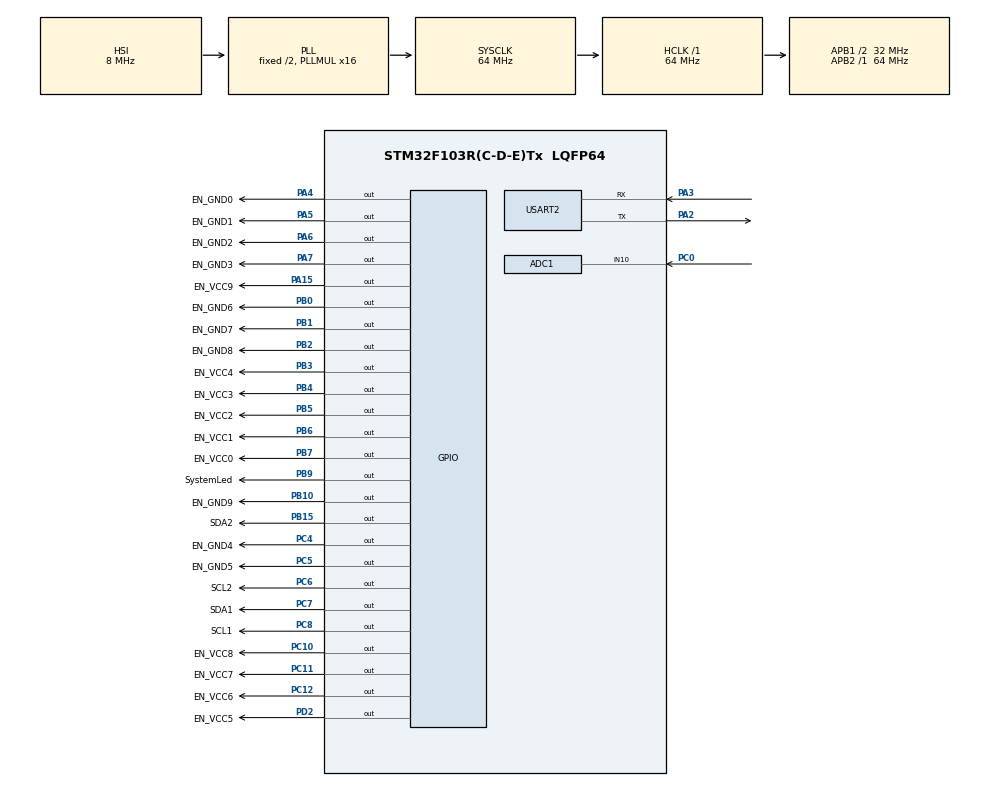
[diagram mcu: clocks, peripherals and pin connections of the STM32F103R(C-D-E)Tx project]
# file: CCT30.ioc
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ADC1.Channel-1\#ChannelRegularConversion=ADC_CHANNEL_10
ADC1.Channel-2\#ChannelRegularConversion=ADC_CHANNEL_TEMPSENSOR
ADC1.Channel-3\#ChannelRegularConversion=ADC_CHANNEL_VREFINT
ADC1.NbrOfConversion=3
ADC1.NbrOfConversionFlag=1
ADC1.Rank-1\#ChannelRegularConversion=1
ADC1.Rank-2\#ChannelRegularConversion=2
ADC1.Rank-3\#ChannelRegularConversion=3
ADC1.SamplingTime-1\#ChannelRegularConversion=ADC_SAMPLETIME_239CYCLES_5
ADC1.SamplingTime-2\#ChannelRegularConversion=ADC_SAMPLETIME_239CYCLES_5
ADC1.SamplingTime-3\#ChannelRegularConversion=ADC_SAMPLETIME_239CYCLES_5
ADC1.master=1
Dma.ADC1.0.Direction=DMA_PERIPH_TO_MEMORY
Dma.ADC1.0.Instance=DMA1_Channel1
Dma.ADC1.0.MemDataAlignment=DMA_MDATAALIGN_WORD
Dma.ADC1.0.MemInc=DMA_MINC_ENABLE
Dma.ADC1.0.Mode=DMA_CIRCULAR
Dma.ADC1.0.PeriphDataAlignment=DMA_PDATAALIGN_WORD
Dma.ADC1.0.PeriphInc=DMA_PINC_DISABLE
Dma.ADC1.0.Priority=DMA_PRIORITY_LOW
Dma.Request0=ADC1
Dma.Request1=USART2_RX
Dma.USART2_RX.1.Direction=DMA_PERIPH_TO_MEMORY
Dma.USART2_RX.1.Instance=DMA1_Channel6
Dma.USART2_RX.1.MemDataAlignment=DMA_MDATAALIGN_BYTE
Dma.USART2_RX.1.MemInc=DMA_MINC_ENABLE
Dma.USART2_RX.1.Mode=DMA_NORMAL
Dma.USART2_RX.1.PeriphDataAlignment=DMA_PDATAALIGN_BYTE
Dma.USART2_RX.1.PeriphInc=DMA_PINC_DISABLE
Dma.USART2_RX.1.Priority=DMA_PRIORITY_LOW
Mcu.Family=STM32F1
Mcu.Name=STM32F103R(C-D-E)Tx
Mcu.Package=LQFP64
NVIC.DMA1_Channel1_IRQn=true\:0\:0\:false\:false\:true\:false\:true\:true
NVIC.DMA1_Channel6_IRQn=true\:0\:0\:false\:false\:true\:false\:true\:true
NVIC.PriorityGroup=NVIC_PRIORITYGROUP_4
NVIC.USART2_IRQn=true\:0\:0\:false\:false\:true\:true\:true\:true
PA13.Mode=Serial_Wire
PA13.Signal=SYS_JTMS-SWDIO
PA14.Mode=Serial_Wire
PA14.Signal=SYS_JTCK-SWCLK
PA15.GPIO_Label=EN_VCC9
PA15.GPIO_ModeDefaultOutputPP=GPIO_MODE_OUTPUT_PP
PA15.GPIO_PuPd=GPIO_NOPULL
PA15.GPIO_Speed=GPIO_SPEED_FREQ_HIGH
PA15.PinState=GPIO_PIN_RESET
PA15.Signal=GPIO_Output
PA2.Mode=Asynchronous
PA2.Signal=USART2_TX
PA3.Mode=Asynchronous
PA3.Signal=USART2_RX
PA4.GPIO_Label=EN_GND0
PA4.GPIO_ModeDefaultOutputPP=GPIO_MODE_OUTPUT_PP
PA4.GPIO_PuPd=GPIO_NOPULL
PA4.GPIO_Speed=GPIO_SPEED_FREQ_HIGH
PA4.PinState=GPIO_PIN_RESET
PA4.Signal=GPIO_Output
PA5.GPIO_Label=EN_GND1
PA5.GPIO_ModeDefaultOutputPP=GPIO_MODE_OUTPUT_PP
PA5.GPIO_PuPd=GPIO_NOPULL
PA5.GPIO_Speed=GPIO_SPEED_FREQ_HIGH
PA5.PinState=GPIO_PIN_RESET
PA5.Signal=GPIO_Output
PA6.GPIO_Label=EN_GND2
PA6.GPIO_ModeDefaultOutputPP=GPIO_MODE_OUTPUT_PP
PA6.GPIO_PuPd=GPIO_NOPULL
PA6.GPIO_Speed=GPIO_SPEED_FREQ_HIGH
PA6.PinState=GPIO_PIN_RESET
PA6.Signal=GPIO_Output
PA7.GPIO_Label=EN_GND3
PA7.GPIO_ModeDefaultOutputPP=GPIO_MODE_OUTPUT_PP
PA7.GPIO_PuPd=GPIO_NOPULL
PA7.GPIO_Speed=GPIO_SPEED_FREQ_HIGH
PA7.PinState=GPIO_PIN_RESET
PA7.Signal=GPIO_Output
PB0.GPIO_Label=EN_GND6
PB0.GPIO_ModeDefaultOutputPP=GPIO_MODE_OUTPUT_PP
PB0.GPIO_PuPd=GPIO_NOPULL
PB0.GPIO_Speed=GPIO_SPEED_FREQ_HIGH
PB0.PinState=GPIO_PIN_RESET
PB0.Signal=GPIO_Output
PB1.GPIO_Label=EN_GND7
PB1.GPIO_ModeDefaultOutputPP=GPIO_MODE_OUTPUT_PP
PB1.GPIO_PuPd=GPIO_NOPULL
PB1.GPIO_Speed=GPIO_SPEED_FREQ_HIGH
PB1.PinState=GPIO_PIN_RESET
PB1.Signal=GPIO_Output
PB10.GPIO_Label=EN_GND9
PB10.GPIO_ModeDefaultOutputPP=GPIO_MODE_OUTPUT_PP
PB10.GPIO_PuPd=GPIO_NOPULL
PB10.GPIO_Speed=GPIO_SPEED_FREQ_HIGH
PB10.PinState=GPIO_PIN_RESET
PB10.Signal=GPIO_Output
PB15.GPIO_Label=SDA2
PB15.GPIO_ModeDefaultOutputPP=GPIO_MODE_OUTPUT_PP
PB15.GPIO_PuPd=GPIO_NOPULL
PB15.GPIO_Speed=GPIO_SPEED_FREQ_HIGH
PB15.PinState=GPIO_PIN_RESET
PB15.Signal=GPIO_Output
PB2.GPIO_Label=EN_GND8
PB2.GPIO_ModeDefaultOutputPP=GPIO_MODE_OUTPUT_PP
PB2.GPIO_PuPd=GPIO_NOPULL
PB2.GPIO_Speed=GPIO_SPEED_FREQ_HIGH
PB2.PinState=GPIO_PIN_RESET
PB2.Signal=GPIO_Output
PB3.GPIO_Label=EN_VCC4
PB3.GPIO_ModeDefaultOutputPP=GPIO_MODE_OUTPUT_PP
PB3.GPIO_PuPd=GPIO_NOPULL
PB3.GPIO_Speed=GPIO_SPEED_FREQ_HIGH
PB3.PinState=GPIO_PIN_RESET
PB3.Signal=GPIO_Output
PB4.GPIO_Label=EN_VCC3
PB4.GPIO_ModeDefaultOutputPP=GPIO_MODE_OUTPUT_PP
PB4.GPIO_PuPd=GPIO_NOPULL
PB4.GPIO_Speed=GPIO_SPEED_FREQ_HIGH
PB4.PinState=GPIO_PIN_RESET
PB4.Signal=GPIO_Output
PB5.GPIO_Label=EN_VCC2
PB5.GPIO_ModeDefaultOutputPP=GPIO_MODE_OUTPUT_PP
PB5.GPIO_PuPd=GPIO_NOPULL
PB5.GPIO_Speed=GPIO_SPEED_FREQ_HIGH
PB5.PinState=GPIO_PIN_RESET
PB5.Signal=GPIO_Output
PB6.GPIO_Label=EN_VCC1
PB6.GPIO_ModeDefaultOutputPP=GPIO_MODE_OUTPUT_PP
PB6.GPIO_PuPd=GPIO_NOPULL
PB6.GPIO_Speed=GPIO_SPEED_FREQ_HIGH
PB6.PinState=GPIO_PIN_RESET
PB6.Signal=GPIO_Output
PB7.GPIO_Label=EN_VCC0
PB7.GPIO_ModeDefaultOutputPP=GPIO_MODE_OUTPUT_PP
PB7.GPIO_PuPd=GPIO_NOPULL
PB7.GPIO_Speed=GPIO_SPEED_FREQ_HIGH
PB7.PinState=GPIO_PIN_RESET
PB7.Signal=GPIO_Output
PB9.GPIO_Label=SystemLed
PB9.Signal=GPIO_Output
PC0.Signal=ADCx_IN10
PC10.GPIO_Label=EN_VCC8
PC10.GPIO_ModeDefaultOutputPP=GPIO_MODE_OUTPUT_PP
PC10.GPIO_PuPd=GPIO_NOPULL
PC10.GPIO_Speed=GPIO_SPEED_FREQ_HIGH
PC10.PinState=GPIO_PIN_RESET
PC10.Signal=GPIO_Output
PC11.GPIO_Label=EN_VCC7
PC11.GPIO_ModeDefaultOutputPP=GPIO_MODE_OUTPUT_PP
PC11.GPIO_PuPd=GPIO_NOPULL
PC11.GPIO_Speed=GPIO_SPEED_FREQ_HIGH
PC11.PinState=GPIO_PIN_RESET
PC11.Signal=GPIO_Output
PC12.GPIO_Label=EN_VCC6
PC12.GPIO_ModeDefaultOutputPP=GPIO_MODE_OUTPUT_PP
PC12.GPIO_PuPd=GPIO_NOPULL
PC12.GPIO_Speed=GPIO_SPEED_FREQ_HIGH
PC12.PinState=GPIO_PIN_RESET
PC12.Signal=GPIO_Output
PC4.GPIO_Label=EN_GND4
PC4.GPIO_ModeDefaultOutputPP=GPIO_MODE_OUTPUT_PP
PC4.GPIO_PuPd=GPIO_NOPULL
PC4.GPIO_Speed=GPIO_SPEED_FREQ_HIGH
PC4.PinState=GPIO_PIN_RESET
PC4.Signal=GPIO_Output
PC5.GPIO_Label=EN_GND5
PC5.GPIO_ModeDefaultOutputPP=GPIO_MODE_OUTPUT_PP
PC5.GPIO_PuPd=GPIO_NOPULL
PC5.GPIO_Speed=GPIO_SPEED_FREQ_HIGH
PC5.PinState=GPIO_PIN_RESET
PC5.Signal=GPIO_Output
PC6.GPIO_Label=SCL2
PC6.GPIO_ModeDefaultOutputPP=GPIO_MODE_OUTPUT_PP
PC6.GPIO_PuPd=GPIO_NOPULL
PC6.GPIO_Speed=GPIO_SPEED_FREQ_HIGH
PC6.PinState=GPIO_PIN_RESET
PC6.Signal=GPIO_Output
PC7.GPIO_Label=SDA1
PC7.GPIO_ModeDefaultOutputPP=GPIO_MODE_OUTPUT_PP
PC7.GPIO_PuPd=GPIO_NOPULL
PC7.GPIO_Speed=GPIO_SPEED_FREQ_HIGH
PC7.PinState=GPIO_PIN_RESET
PC7.Signal=GPIO_Output
PC8.GPIO_Label=SCL1
PC8.GPIO_ModeDefaultOutputPP=GPIO_MODE_OUTPUT_PP
PC8.GPIO_PuPd=GPIO_NOPULL
PC8.GPIO_Speed=GPIO_SPEED_FREQ_HIGH
PC8.PinState=GPIO_PIN_RESET
PC8.Signal=GPIO_Output
PD2.GPIO_Label=EN_VCC5
PD2.GPIO_ModeDefaultOutputPP=GPIO_MODE_OUTPUT_PP
PD2.GPIO_PuPd=GPIO_NOPULL
PD2.GPIO_Speed=GPIO_SPEED_FREQ_HIGH
PD2.PinState=GPIO_PIN_RESET
PD2.Signal=GPIO_Output
ProjectManager.HeapSize=0x200
ProjectManager.StackSize=0x400
ProjectManager.TargetToolchain=MDK-ARM V5.32
RCC.ADCPresc=RCC_ADCPCLK2_DIV6
RCC.AHBFreq_Value=64000000
RCC.APB1CLKDivider=RCC_HCLK_DIV2
RCC.APB1Freq_Value=32000000
RCC.APB1TimFreq_Value=64000000
RCC.APB2Freq_Value=64000000
RCC.APB2TimFreq_Value=64000000
RCC.HCLKFreq_Value=64000000
RCC.PLLMUL=RCC_PLL_MUL16
RCC.SYSCLKFreq_VALUE=64000000
RCC.SYSCLKSource=RCC_SYSCLKSOURCE_PLLCLK
RCC.USBFreq_Value=64000000
SH.ADCx_IN10.0=ADC1_IN10,IN10
USART2.VirtualMode=VM_ASYNC
VP_ADC1_TempSens_Input.Mode=IN-TempSens
VP_ADC1_Vref_Input.Mode=IN-Vrefint
board=custom

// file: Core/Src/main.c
/* USER CODE BEGIN Header */
/**
  ******************************************************************************
  * @file           : main.c
  * @brief          : Main program body
  ******************************************************************************
  * @attention
  *
  * Copyright (c) 2023 STMicroelectronics.
  * All rights reserved.
  *
  * This software is licensed under terms that can be found in the LICENSE file
  * in the root directory of this software component.
  * If no LICENSE file comes with this software, it is provided AS-IS.
  *
  ******************************************************************************
  */
/* USER CODE END Header */
#include "main.h"

ADC_HandleTypeDef hadc1;
DMA_HandleTypeDef hdma_adc1;

UART_HandleTypeDef huart2;
DMA_HandleTypeDef hdma_usart2_rx;

void SystemClock_Config(void);
static void MX_GPIO_Init(void);
static void MX_DMA_Init(void);
static void MX_USART2_UART_Init(void);
static void MX_ADC1_Init(void);
/* USER CODE BEGIN PFP */
 void JQStart(void);
  void jSystemRun(void);
/* USER CODE END PFP */

int main(void)
{

  /* MCU Configuration--------------------------------------------------------*/

  /* Reset of all peripherals, Initializes the Flash interface and the Systick. */
  HAL_Init();

  /* Configure the system clock */
  SystemClock_Config();

  /* Initialize all configured peripherals */
  MX_GPIO_Init();
  MX_DMA_Init();
  MX_USART2_UART_Init();
  MX_ADC1_Init();

  /* Infinite loop */
  /* USER CODE BEGIN WHILE */
  while (1)
  {
		jSystemRun();
    /* USER CODE END WHILE */

  }
}

void SystemClock_Config(void)
{
  RCC_OscInitTypeDef RCC_OscInitStruct = {0};
  RCC_ClkInitTypeDef RCC_ClkInitStruct = {0};
  RCC_PeriphCLKInitTypeDef PeriphClkInit = {0};

  /** Initializes the RCC Oscillators according to the specified parameters
  * in the RCC_OscInitTypeDef structure.
  */
  RCC_OscInitStruct.OscillatorType = RCC_OSCILLATORTYPE_HSI;
  RCC_OscInitStruct.HSIState = RCC_HSI_ON;
  RCC_OscInitStruct.HSICalibrationValue = RCC_HSICALIBRATION_DEFAULT;
  RCC_OscInitStruct.PLL.PLLState = RCC_PLL_ON;
  RCC_OscInitStruct.PLL.PLLSource = RCC_PLLSOURCE_HSI_DIV2;
  RCC_OscInitStruct.PLL.PLLMUL = RCC_PLL_MUL16;
  if (HAL_RCC_OscConfig(&RCC_OscInitStruct) != HAL_OK)
  {
    Error_Handler();
  }

  /** Initializes the CPU, AHB and APB buses clocks
  */
  RCC_ClkInitStruct.ClockType = RCC_CLOCKTYPE_HCLK|RCC_CLOCKTYPE_SYSCLK
                              |RCC_CLOCKTYPE_PCLK1|RCC_CLOCKTYPE_PCLK2;
  RCC_ClkInitStruct.SYSCLKSource = RCC_SYSCLKSOURCE_PLLCLK;
  RCC_ClkInitStruct.AHBCLKDivider = RCC_SYSCLK_DIV1;
  RCC_ClkInitStruct.APB1CLKDivider = RCC_HCLK_DIV2;
  RCC_ClkInitStruct.APB2CLKDivider = RCC_HCLK_DIV1;

  if (HAL_RCC_ClockConfig(&RCC_ClkInitStruct, FLASH_LATENCY_2) != HAL_OK)
  {
    Error_Handler();
  }
  PeriphClkInit.PeriphClockSelection = RCC_PERIPHCLK_ADC;
  PeriphClkInit.AdcClockSelection = RCC_ADCPCLK2_DIV6;
  if (HAL_RCCEx_PeriphCLKConfig(&PeriphClkInit) != HAL_OK)
  {
    Error_Handler();
  }
}

static void MX_ADC1_Init(void)
{

  ADC_ChannelConfTypeDef sConfig = {0};

  /** Common config
  */
  hadc1.Instance = ADC1;
  hadc1.Init.ScanConvMode = ADC_SCAN_ENABLE;
  hadc1.Init.ContinuousConvMode = DISABLE;
  hadc1.Init.DiscontinuousConvMode = DISABLE;
  hadc1.Init.ExternalTrigConv = ADC_SOFTWARE_START;
  hadc1.Init.DataAlign = ADC_DATAALIGN_RIGHT;
  hadc1.Init.NbrOfConversion = 3;
  if (HAL_ADC_Init(&hadc1) != HAL_OK)
  {
    Error_Handler();
  }

  /** Configure Regular Channel
  */
  sConfig.Channel = ADC_CHANNEL_10;
  sConfig.Rank = ADC_REGULAR_RANK_1;
  sConfig.SamplingTime = ADC_SAMPLETIME_239CYCLES_5;
  if (HAL_ADC_ConfigChannel(&hadc1, &sConfig) != HAL_OK)
  {
    Error_Handler();
  }

  /** Configure Regular Channel
  */
  sConfig.Channel = ADC_CHANNEL_TEMPSENSOR;
  sConfig.Rank = ADC_REGULAR_RANK_2;
  if (HAL_ADC_ConfigChannel(&hadc1, &sConfig) != HAL_OK)
  {
    Error_Handler();
  }

  /** Configure Regular Channel
  */
  sConfig.Channel = ADC_CHANNEL_VREFINT;
  sConfig.Rank = ADC_REGULAR_RANK_3;
  if (HAL_ADC_ConfigChannel(&hadc1, &sConfig) != HAL_OK)
  {
    Error_Handler();
  }

}

static void MX_USART2_UART_Init(void)
{

  huart2.Instance = USART2;
  huart2.Init.BaudRate = 115200;
  huart2.Init.WordLength = UART_WORDLENGTH_8B;
  huart2.Init.StopBits = UART_STOPBITS_1;
  huart2.Init.Parity = UART_PARITY_NONE;
  huart2.Init.Mode = UART_MODE_TX_RX;
  huart2.Init.HwFlowCtl = UART_HWCONTROL_NONE;
  huart2.Init.OverSampling = UART_OVERSAMPLING_16;
  if (HAL_UART_Init(&huart2) != HAL_OK)
  {
    Error_Handler();
  }

}

static void MX_DMA_Init(void)
{

  /* DMA controller clock enable */
  __HAL_RCC_DMA1_CLK_ENABLE();

  /* DMA interrupt init */
  /* DMA1_Channel1_IRQn interrupt configuration */
  HAL_NVIC_SetPriority(DMA1_Channel1_IRQn, 0, 0);
  HAL_NVIC_EnableIRQ(DMA1_Channel1_IRQn);
  /* DMA1_Channel6_IRQn interrupt configuration */
  HAL_NVIC_SetPriority(DMA1_Channel6_IRQn, 0, 0);
  HAL_NVIC_EnableIRQ(DMA1_Channel6_IRQn);

}

static void MX_GPIO_Init(void)
{
  GPIO_InitTypeDef GPIO_InitStruct = {0};

  /* GPIO Ports Clock Enable */
  __HAL_RCC_GPIOC_CLK_ENABLE();
  __HAL_RCC_GPIOA_CLK_ENABLE();
  __HAL_RCC_GPIOB_CLK_ENABLE();
  __HAL_RCC_GPIOD_CLK_ENABLE();

  /*Configure GPIO pin Output Level */
  HAL_GPIO_WritePin(GPIOA, EN_GND0_Pin|EN_GND1_Pin|EN_GND2_Pin|EN_GND3_Pin
                          |EN_VCC9_Pin, GPIO_PIN_RESET);

  /*Configure GPIO pin Output Level */
  HAL_GPIO_WritePin(GPIOC, EN_GND4_Pin|EN_GND5_Pin|SCL2_Pin|SDA1_Pin
                          |SCL1_Pin|EN_VCC8_Pin|EN_VCC7_Pin|EN_VCC6_Pin, GPIO_PIN_RESET);

  /*Configure GPIO pin Output Level */
  HAL_GPIO_WritePin(GPIOB, EN_GND6_Pin|EN_GND7_Pin|EN_GND8_Pin|EN_GND9_Pin
                          |SDA2_Pin|EN_VCC4_Pin|EN_VCC3_Pin|EN_VCC2_Pin
                          |EN_VCC1_Pin|EN_VCC0_Pin|SystemLed_Pin, GPIO_PIN_RESET);

  /*Configure GPIO pin Output Level */
  HAL_GPIO_WritePin(EN_VCC5_GPIO_Port, EN_VCC5_Pin, GPIO_PIN_RESET);

  /*Configure GPIO pins : EN_GND0_Pin EN_GND1_Pin EN_GND2_Pin EN_GND3_Pin
                           EN_VCC9_Pin */
  GPIO_InitStruct.Pin = EN_GND0_Pin|EN_GND1_Pin|EN_GND2_Pin|EN_GND3_Pin
                          |EN_VCC9_Pin;
  GPIO_InitStruct.Mode = GPIO_MODE_OUTPUT_PP;
  GPIO_InitStruct.Pull = GPIO_NOPULL;
  GPIO_InitStruct.Speed = GPIO_SPEED_FREQ_HIGH;
  HAL_GPIO_Init(GPIOA, &GPIO_InitStruct);

  /*Configure GPIO pins : EN_GND4_Pin EN_GND5_Pin SCL2_Pin SDA1_Pin
                           SCL1_Pin EN_VCC8_Pin EN_VCC7_Pin EN_VCC6_Pin */
  GPIO_InitStruct.Pin = EN_GND4_Pin|EN_GND5_Pin|SCL2_Pin|SDA1_Pin
                          |SCL1_Pin|EN_VCC8_Pin|EN_VCC7_Pin|EN_VCC6_Pin;
  GPIO_InitStruct.Mode = GPIO_MODE_OUTPUT_PP;
  GPIO_InitStruct.Pull = GPIO_NOPULL;
  GPIO_InitStruct.Speed = GPIO_SPEED_FREQ_HIGH;
  HAL_GPIO_Init(GPIOC, &GPIO_InitStruct);

  /*Configure GPIO pins : EN_GND6_Pin EN_GND7_Pin EN_GND8_Pin EN_GND9_Pin
                           SDA2_Pin EN_VCC4_Pin EN_VCC3_Pin EN_VCC2_Pin
                           EN_VCC1_Pin EN_VCC0_Pin */
  GPIO_InitStruct.Pin = EN_GND6_Pin|EN_GND7_Pin|EN_GND8_Pin|EN_GND9_Pin
                          |SDA2_Pin|EN_VCC4_Pin|EN_VCC3_Pin|EN_VCC2_Pin
                          |EN_VCC1_Pin|EN_VCC0_Pin;
  GPIO_InitStruct.Mode = GPIO_MODE_OUTPUT_PP;
  GPIO_InitStruct.Pull = GPIO_NOPULL;
  GPIO_InitStruct.Speed = GPIO_SPEED_FREQ_HIGH;
  HAL_GPIO_Init(GPIOB, &GPIO_InitStruct);

  /*Configure GPIO pin : EN_VCC5_Pin */
  GPIO_InitStruct.Pin = EN_VCC5_Pin;
  GPIO_InitStruct.Mode = GPIO_MODE_OUTPUT_PP;
  GPIO_InitStruct.Pull = GPIO_NOPULL;
  GPIO_InitStruct.Speed = GPIO_SPEED_FREQ_HIGH;
  HAL_GPIO_Init(EN_VCC5_GPIO_Port, &GPIO_InitStruct);

  /*Configure GPIO pin : SystemLed_Pin */
  GPIO_InitStruct.Pin = SystemLed_Pin;
  GPIO_InitStruct.Mode = GPIO_MODE_OUTPUT_PP;
  GPIO_InitStruct.Pull = GPIO_NOPULL;
  GPIO_InitStruct.Speed = GPIO_SPEED_FREQ_LOW;
  HAL_GPIO_Init(SystemLed_GPIO_Port, &GPIO_InitStruct);

}

void Error_Handler(void)
{
  __disable_irq();
  while (1)
  {
  }
}
